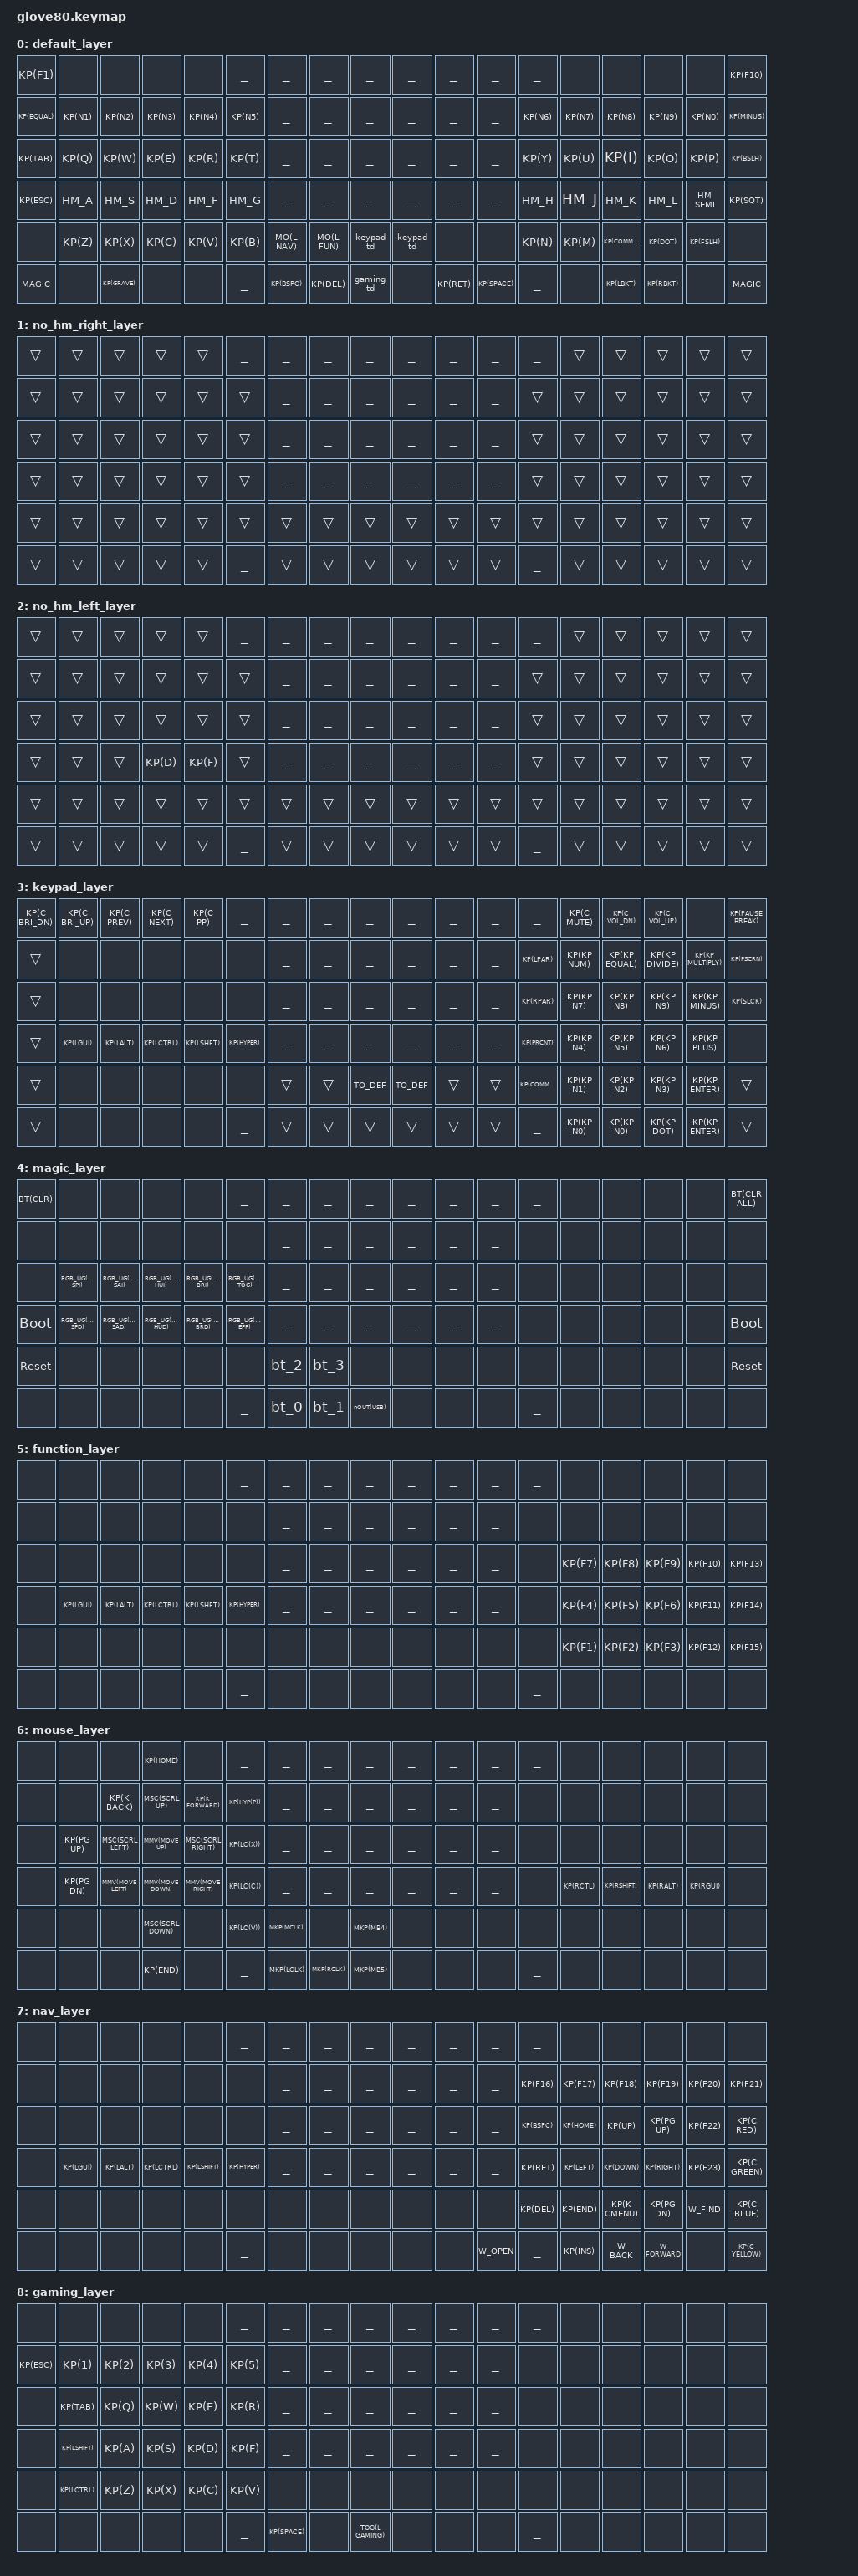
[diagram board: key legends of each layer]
/*
 * Copyright (c) 2020 The ZMK Contributors
 *
 * SPDX-License-Identifier: MIT
 */

#include <behaviors.dtsi>
#include <dt-bindings/zmk/keys.h>
#include <dt-bindings/zmk/bt.h>
#include <dt-bindings/zmk/ext_power.h>
#include <dt-bindings/zmk/outputs.h>
#include <dt-bindings/zmk/rgb.h>

#include "../shared/common.dtsi"

/ {
    behaviors {
        gaming_td: gaming_td {
            compatible = "zmk,behavior-tap-dance";
            label = "GAMING_CAPS_TAP_DANCE";
            #binding-cells = <0>;
            tapping-term-ms = <200>;
            bindings = <&caps_word>, <&tog L_GAMING>;
        };


        hml: home_row_mod_left {
            compatible = "zmk,behavior-hold-tap";
            #binding-cells = <2>;
            flavor = "balanced";
            // require-prior-idle-ms = <150>;
            tapping-term-ms = <280>;
            quick-tap-ms = <175>;
            bindings = <&kp>, <&kp>;
            hold-trigger-key-positions = <5 6 7 8 9 16 17 18 19 20 21 28 29 30 31 32 33 40 41 42 43 44 45 55 56 57 58 59 60 61 62 63 72 73 74 75 76 77 78 79>; // List of keys on the right side of the keyboard
            hold-trigger-on-release;
        };
        hmr: home_row_mod_right {
            compatible = "zmk,behavior-hold-tap";
            #binding-cells = <2>;
            flavor = "balanced";
            // require-prior-idle-ms = <150>;
            tapping-term-ms = <280>;
            quick-tap-ms = <175>;
            bindings = <&kp_no_hm_left>, <&kp>;
            hold-trigger-key-positions = <0 1 2 3 4 10 11 12 13 14 15 22 23 24 25 26 27 34 35 36 37 38 39 46 47 48 49 50 51 52 53 54 64 65 66 67 68 69 70 71>; // List of keys on the left side of the keyboard
            hold-trigger-on-release;
        };

        slash_undo: slash_undo {
            compatible = "zmk,behavior-mod-morph";
            #binding-cells = <0>;
            bindings = <&kp FSLH>, <&kp K_UNDO>;
            mods = <(MOD_RCTL|MOD_LCTL)>;
        };
    };

    #define POS_L11 0
    #define POS_L12 1
    #define POS_L13 2
    #define POS_L14 3
    #define POS_L15 4
    #define POS_R11 5
    #define POS_R12 6
    #define POS_R13 7
    #define POS_R14 8
    #define POS_R15 9
    #define POS_L21 10
    #define POS_L22 11
    #define POS_L23 12
    #define POS_L24 13
    #define POS_L25 14
    #define POS_L26 15
    #define POS_R21 16
    #define POS_R22 17
    #define POS_R23 18
    #define POS_R24 19
    #define POS_R25 20
    #define POS_R26 21
    #define POS_L31 22
    #define POS_L32 23
    #define POS_L33 24
    #define POS_L34 25
    #define POS_L35 26
    #define POS_L36 27
    #define POS_R31 28
    #define POS_R32 29
    #define POS_R33 30
    #define POS_R34 31
    #define POS_R35 32
    #define POS_R36 33
    #define POS_L41 34
    #define POS_L42 35
    #define POS_L43 36
    #define POS_L44 37
    #define POS_L45 38
    #define POS_L46 39
    #define POS_R41 40
    #define POS_R42 41
    #define POS_R43 42
    #define POS_R44 43
    #define POS_R45 44
    #define POS_R46 45
    #define POS_L51 46
    #define POS_L52 47
    #define POS_L53 48
    #define POS_L54 49
    #define POS_L55 50
    #define POS_L56 51
    #define POS_TL11 52
    #define POS_TL12 53
    #define POS_TL13 54
    #define POS_TR11 55
    #define POS_TR12 56
    #define POS_TR13 57
    #define POS_R51 58
    #define POS_R52 59
    #define POS_R53 60
    #define POS_R54 61
    #define POS_R55 62
    #define POS_R56 63
    #define POS_L61 64
    #define POS_L62 65
    #define POS_L63 66
    #define POS_L64 67
    #define POS_L65 68
    #define POS_TL21 69
    #define POS_TL22 70
    #define POS_TL23 71
    #define POS_TR21 72
    #define POS_TR22 73
    #define POS_TR23 74
    #define POS_R61 75
    #define POS_R62 76
    #define POS_R63 77
    #define POS_R64 78
    #define POS_R65 79

    /* combos {
        compatible = "zmk,combos";

        combo_function_layer {
            timeout-ms = <50>;
            key-positions = <POS_TL13 POS_TL23>;
            bindings = <&mo L_FUN>;
        };

        combo_mouse_layer {
            timeout-ms = <50>;
            key-positions = <POS_TR11 POS_TR12>;
            bindings = <&mo L_MOUSE>;
        };
    };*/

    keymap {
        compatible = "zmk,keymap";

        /*
        _layer {
            bindings = <
            &none &none &none &none &none _____ _____ _____ _____ _____ _____ _____ _____ &none &none &none &none &none
            &none &none &none &none &none &none _____ _____ _____ _____ _____ _____ &none &none &none &none &none &none
            &none &none &none &none &none &none _____ _____ _____ _____ _____ _____ &none &none &none &none &none &none
            &none &none &none &none &none &none _____ _____ _____ _____ _____ _____ &none &none &none &none &none &none
            &none &none &none &none &none &none &none &none &none &none &none &none &none &none &none &none &none &none
            &none &none &none &none &none _____ &none &none &none &none &none &none _____ &none &none &none &none &none
            >;
        };
        _layer {
            bindings = <
            &trans &trans &trans &trans &trans _____  _____  _____  _____  _____  _____  _____  _____  &trans &trans &trans &trans &trans
            &trans &trans &trans &trans &trans &trans _____  _____  _____  _____  _____  _____  &trans &trans &trans &trans &trans &trans
            &trans &trans &trans &trans &trans &trans _____  _____  _____  _____  _____  _____  &trans &trans &trans &trans &trans &trans
            &trans &trans &trans &trans &trans &trans _____  _____  _____  _____  _____  _____  &trans &trans &trans &trans &trans &trans
            &trans &trans &trans &trans &trans &trans &trans &trans &trans &trans &trans &trans &trans &trans &trans &trans &trans &trans
            &trans &trans &trans &trans &trans _____  &trans &trans &trans &trans &trans &trans _____  &trans &trans &trans &trans &trans
            >;
        };
        */

        default_layer {
            // ---------------------------------------------------------------------------------------------------------------------------------
            // |  F1   |  F2 |  F3 |  F4  |  F5  |                                                               |  F6   |  F7   |  F8  |   F9  |  F10 |  10 (0-9): l:0-4 r:5-9
            // |  =    |  1  |  2  |  3   |  4   |  5   |                                                 |  6   |   7   |   8   |  9   |   0   |   -  |  12 (10-21) l:10-15 r:16-21
            // |  TAB  |  Q  |  W  |  E   |  R   |  T   |                                                 |  Y   |   U   |   I   |  O   |   P   |   \  |  12 (22-33) l:22-27 r:28-33
            // |  ESC  |  A  |  S  |  D   |  F   |  G   |                                                 |  H   |   J   |   K   |  L   |   ;   |   '  |  12 (34-45) l:34-39 r:40-45
            // |   `   |  Z  |  X  |  C   |  V   |  B   | LSHFT | LCTRL | LOWER | | LGUI  | RCTRL | RSHFT |  N   |   M   |   ,   |  .   |   /   | PGUP |  6+3+3+6 (46-63) l:46-54 r:55-63
            // | MAGIC | HOME| END | LEFT | RIGHT|      | BSPC  | DEL   | LALT  | | RALT  | RET   | SPACE |      |  UP   | DOWN  |  [   |   ]   | PGDN |  5+3+3+5 (64-79) l:64-71 r:72-79

            bindings = <
            KP(F1)    &none  &none     &none  &none  _____  _____     _____     _____      _____      _____   _____     _____  &none  &none     &none    &none    KP(F10)
            KP(EQUAL) KP(N1) KP(N2)    KP(N3) KP(N4) KP(N5) _____     _____     _____      _____      _____   _____     KP(N6) KP(N7) KP(N8)    KP(N9)   KP(N0)   KP(MINUS)
            KP(TAB)   KP(Q)  KP(W)     KP(E)  KP(R)  KP(T)  _____     _____     _____      _____      _____   _____     KP(Y)  KP(U)  KP(I)     KP(O)    KP(P)    KP(BSLH)
            KP(ESC)   HM_A   HM_S      HM_D   HM_F   HM_G   _____     _____     _____      _____      _____   _____     HM_H   HM_J   HM_K      HM_L     HM_SEMI  KP(SQT)
            &none     KP(Z)  KP(X)     KP(C)  KP(V)  KP(B)  MO(L_NAV) MO(L_FUN) &keypad_td &keypad_td &none   &none     KP(N)  KP(M)  KP(COMMA) KP(DOT)  KP(FSLH) &none
            MAGIC     &none  KP(GRAVE) &none  &none  _____  KP(BSPC)  KP(DEL)   &gaming_td &none      KP(RET) KP(SPACE) _____  &none  KP(LBKT)  KP(RBKT) &none    MAGIC
            >;
        };

        no_hm_right_layer {
            bindings = <
            &trans &trans &trans &trans &trans _____  _____  _____  _____  _____  _____  _____  _____  &trans &trans &trans &trans &trans
            &trans &trans &trans &trans &trans &trans _____  _____  _____  _____  _____  _____  &trans &trans &trans &trans &trans &trans
            &trans &trans &trans &trans &trans &trans _____  _____  _____  _____  _____  _____  &trans &trans &trans &trans &trans &trans
            &trans &trans &trans &trans &trans &trans _____  _____  _____  _____  _____  _____  &trans &trans &trans &trans &trans &trans
            &trans &trans &trans &trans &trans &trans &trans &trans &trans &trans &trans &trans &trans &trans &trans &trans &trans &trans
            &trans &trans &trans &trans &trans _____  &trans &trans &trans &trans &trans &trans _____  &trans &trans &trans &trans &trans
            >;
        };

        no_hm_left_layer {
            bindings = <
            &trans &trans &trans &trans &trans _____  _____  _____  _____  _____  _____  _____  _____  &trans &trans &trans &trans &trans
            &trans &trans &trans &trans &trans &trans _____  _____  _____  _____  _____  _____  &trans &trans &trans &trans &trans &trans
            &trans &trans &trans &trans &trans &trans _____  _____  _____  _____  _____  _____  &trans &trans &trans &trans &trans &trans
            &trans &trans &trans KP(D)  KP(F)  &trans _____  _____  _____  _____  _____  _____  &trans &trans &trans &trans &trans &trans
            &trans &trans &trans &trans &trans &trans &trans &trans &trans &trans &trans &trans &trans &trans &trans &trans &trans &trans
            &trans &trans &trans &trans &trans _____  &trans &trans &trans &trans &trans &trans _____  &trans &trans &trans &trans &trans
            >;
        };

        keypad_layer {
            bindings = <
            KP(C_BRI_DN) KP(C_BRI_UP) KP(C_PREV) KP(C_NEXT) KP(C_PP)  _____     _____  _____  _____  _____  _____  _____  _____     KP(C_MUTE) KP(C_VOL_DN) KP(C_VOL_UP)  &none           KP(PAUSE_BREAK)
            &trans       &none        &none      &none      &none     &none     _____  _____  _____  _____  _____  _____  KP(LPAR)  KP(KP_NUM) KP(KP_EQUAL) KP(KP_DIVIDE) KP(KP_MULTIPLY) KP(PSCRN)
            &trans       &none        &none      &none      &none     &none     _____  _____  _____  _____  _____  _____  KP(RPAR)  KP(KP_N7)  KP(KP_N8)    KP(KP_N9)     KP(KP_MINUS)    KP(SLCK)
            &trans       KP(LGUI)     KP(LALT)   KP(LCTRL)  KP(LSHFT) KP(HYPER) _____  _____  _____  _____  _____  _____  KP(PRCNT) KP(KP_N4)  KP(KP_N5)    KP(KP_N6)     KP(KP_PLUS)     &none
            &trans       &none        &none      &none      &none     &none     &trans &trans TO_DEF TO_DEF &trans &trans KP(COMMA) KP(KP_N1)  KP(KP_N2)    KP(KP_N3)     KP(KP_ENTER)    &trans
            &trans       &none        &none      &none      &none     _____     &trans &trans &trans &trans &trans &trans _____     KP(KP_N0)  KP(KP_N0)    KP(KP_DOT)    KP(KP_ENTER)    &trans
            >;
        };

        magic_layer {
            bindings = <
            BT(CLR)     &none           &none           &none           &none           _____           _____ _____ _____     _____ _____ _____ _____ &none &none &none &none BT(CLR_ALL)
            &none       &none           &none           &none           &none           &none           _____ _____ _____     _____ _____ _____ &none &none &none &none &none &none
            &none       RGB_UG(RGB_SPI) RGB_UG(RGB_SAI) RGB_UG(RGB_HUI) RGB_UG(RGB_BRI) RGB_UG(RGB_TOG) _____ _____ _____     _____ _____ _____ &none &none &none &none &none &none
            &bootloader RGB_UG(RGB_SPD) RGB_UG(RGB_SAD) RGB_UG(RGB_HUD) RGB_UG(RGB_BRD) RGB_UG(RGB_EFF) _____ _____ _____     _____ _____ _____ &none &none &none &none &none &bootloader
            &sys_reset  &none           &none           &none           &none           &none           &bt_2 &bt_3 &none     &none &none &none &none &none &none &none &none &sys_reset
            &none       &none           &none           &none           &none           _____           &bt_0 &bt_1 nOUT(USB) &none &none &none _____ &none &none &none &none &none
            >;
        };

        function_layer {
            bindings = <
            &none &none    &none    &none     &none     _____     _____ _____ _____ _____ _____ _____ _____ &none  &none  &none  &none   &none
            &none &none    &none    &none     &none     &none     _____ _____ _____ _____ _____ _____ &none &none  &none  &none  &none   &none
            &none &none    &none    &none     &none     &none     _____ _____ _____ _____ _____ _____ &none KP(F7) KP(F8) KP(F9) KP(F10) KP(F13)
            &none KP(LGUI) KP(LALT) KP(LCTRL) KP(LSHFT) KP(HYPER) _____ _____ _____ _____ _____ _____ &none KP(F4) KP(F5) KP(F6) KP(F11) KP(F14)
            &none &none    &none    &none     &none     &none     &none &none &none &none &none &none &none KP(F1) KP(F2) KP(F3) KP(F12) KP(F15)
            &none &none    &none    &none     &none     _____     &none &none &none &none &none &none _____ &none  &none  &none  &none   &none
            >;
        };

        mouse_layer {
            bindings = <
            &none &none     &none          KP(HOME)       &none           _____      _____     _____     _____    _____ _____ _____ _____ &none    &none      &none    &none    &none
            &none &none     KP(K_BACK)     MSC(SCRL_UP)   KP(K_FORWARD)   KP(HYP(P)) _____     _____     _____    _____ _____ _____ &none &none    &none      &none    &none    &none
            &none KP(PG_UP) MSC(SCRL_LEFT) MMV(MOVE_UP)   MSC(SCRL_RIGHT) KP(LC(X))  _____     _____     _____    _____ _____ _____ &none &none    &none      &none    &none    &none
            &none KP(PG_DN) MMV(MOVE_LEFT) MMV(MOVE_DOWN) MMV(MOVE_RIGHT) KP(LC(C))  _____     _____     _____    _____ _____ _____ &none KP(RCTL) KP(RSHIFT) KP(RALT) KP(RGUI) &none
            &none &none     &none          MSC(SCRL_DOWN) &none           KP(LC(V))  MKP(MCLK) &none     MKP(MB4) &none &none &none &none &none    &none      &none    &none    &none
            &none &none     &none          KP(END)        &none           _____      MKP(LCLK) MKP(RCLK) MKP(MB5) &none &none &none _____ &none    &none      &none    &none    &none
            >;
        };

        nav_layer {
            bindings = <
            &none &none    &none    &none     &none      _____     _____ _____ _____ _____ _____ _____  _____    &none    &none       &none     &none   &none
            &none &none    &none    &none     &none      &none     _____ _____ _____ _____ _____ _____  KP(F16)  KP(F17)  KP(F18)     KP(F19)   KP(F20) KP(F21)
            &none &none    &none    &none     &none      &none     _____ _____ _____ _____ _____ _____  KP(BSPC) KP(HOME) KP(UP)      KP(PG_UP) KP(F22) KP(C_RED)
            &none KP(LGUI) KP(LALT) KP(LCTRL) KP(LSHIFT) KP(HYPER) _____ _____ _____ _____ _____ _____  KP(RET)  KP(LEFT) KP(DOWN)    KP(RIGHT) KP(F23) KP(C_GREEN)
            &none &none    &none    &none     &none      &none     &none &none &none &none &none &none  KP(DEL)  KP(END)  KP(K_CMENU) KP(PG_DN) W_FIND  KP(C_BLUE)
            &none &none    &none    &none     &none      _____     &none &none &none &none &none W_OPEN _____    KP(INS)  W_BACK      W_FORWARD &none   KP(C_YELLOW)
            >;
        };

        gaming_layer {
            bindings = <
            &none   &none      &none &none &none _____ _____     _____ _____         _____ _____ _____ _____ &none &none &none &none &none
            KP(ESC) KP(1)      KP(2) KP(3) KP(4) KP(5) _____     _____ _____         _____ _____ _____ &none &none &none &none &none &none
            &none   KP(TAB)    KP(Q) KP(W) KP(E) KP(R) _____     _____ _____         _____ _____ _____ &none &none &none &none &none &none
            &none   KP(LSHIFT) KP(A) KP(S) KP(D) KP(F) _____     _____ _____         _____ _____ _____ &none &none &none &none &none &none
            &none   KP(LCTRL)  KP(Z) KP(X) KP(C) KP(V) &none     &none &none         &none &none &none &none &none &none &none &none &none
            &none   &none      &none &none &none _____ KP(SPACE) &none TOG(L_GAMING) &none &none &none _____ &none &none &none &none &none
            >;
        };
    };
};
